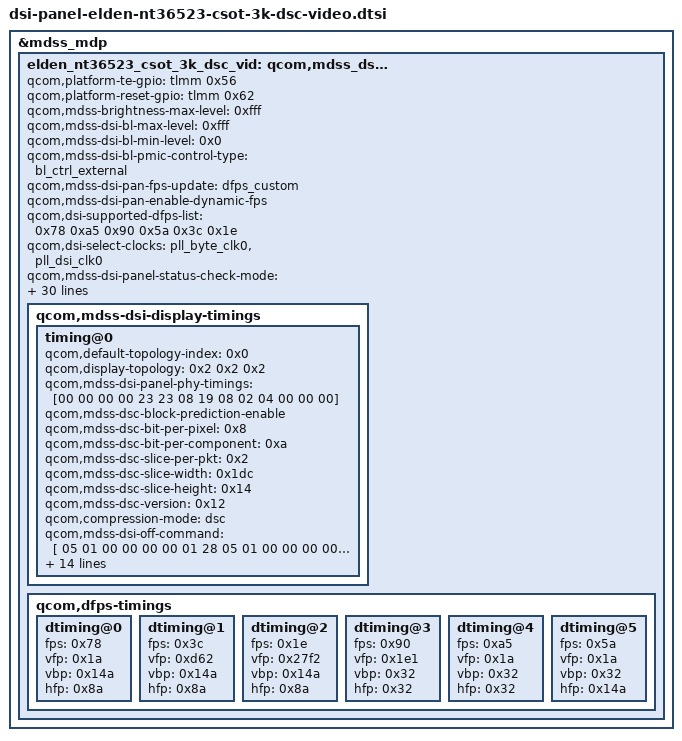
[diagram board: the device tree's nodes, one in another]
// SPDX-License-Identifier: GPL-2.0-only

&mdss_mdp {
	elden_nt36523_csot_3k_dsc_vid: qcom,mdss_dsi_elden_nt36523_csot_3k_dsc_vid {
		qcom,platform-te-gpio = <&tlmm 0x56 0x0>;
		qcom,platform-reset-gpio = <&tlmm 0x62 0x0>;
		qcom,mdss-brightness-max-level = <0xfff>;
		qcom,mdss-dsi-bl-max-level = <0xfff>;
		qcom,mdss-dsi-bl-min-level = <0x0>;
		qcom,mdss-dsi-bl-pmic-control-type = "bl_ctrl_external";
		qcom,mdss-dsi-pan-fps-update = "dfps_custom";
		qcom,mdss-dsi-pan-enable-dynamic-fps;
		qcom,dsi-supported-dfps-list = <0x78 0xa5 0x90 0x5a 0x3c 0x1e>;
		qcom,dsi-select-clocks = "pll_byte_clk0", "pll_dsi_clk0";
		qcom,mdss-dsi-panel-status-check-mode = "te_signal_check";
		qcom,esd-check-enabled;
		qcom,ulps-enabled;
		qcom,mdss-dsi-panel-blackness-level = <0xc9e>;
		qcom,mdss-dsi-panel-peak-brightness = <0x989680>;
		qcom,mdss-dsi-panel-hdr-color-primaries = <0x38a4 0x3c8c 0x7d00 0x4268 0x3c8c 0x7530 0x1f40 0xbb8>;
		qcom,mdss-dsi-panel-hdr-enabled;
		qcom,mdss-dsi-reset-sequence = <0x0 0xb 0x1 0x1 0x0 0x3 0x1 0xa>;
		qcom,mdss-dsi-lp11-init;
		qcom,mdss-pan-physical-height-dimension = <0xbe>;
		qcom,mdss-pan-physical-width-dimension = <0x76>;
		qcom,panel-cphy-mode;
		qcom,mdss-dsi-mdp-trigger = "none";
		qcom,mdss-dsi-dma-trigger = "trigger_sw";
		qcom,mdss-dsi-lane-2-state;
		qcom,mdss-dsi-lane-1-state;
		qcom,mdss-dsi-lane-0-state;
		qcom,mdss-dsi-bllp-eof-power-mode;
		qcom,mdss-dsi-bllp-power-mode;
		qcom,mdss-dsi-traffic-mode = "burst_mode";
		qcom,mdss-dsi-bpp = <0x1e>;
		qcom,mdss-dsi-stream = <0x0>;
		qcom,mdss-dsi-virtual-channel-id = <0x0>;
		qcom,dsi-phy-num = <0x0 0x1>;
		qcom,dsi-ctrl-num = <0x0 0x1>;
		qcom,mdss-dsi-panel-type = "dsi_video_mode";
		qcom,mdss-dsi-panel-name = "nt36523 3k fhd plus 165Hz CPHY video panel";

		qcom,mdss-dsi-display-timings {

			timing@0 {
				qcom,default-topology-index = <0x0>;
				qcom,display-topology = <0x2 0x2 0x2>;
				qcom,mdss-dsi-panel-phy-timings = [00 00 00 00 23 23 08 19 08 02 04 00 00 00];
				qcom,mdss-dsc-block-prediction-enable;
				qcom,mdss-dsc-bit-per-pixel = <0x8>;
				qcom,mdss-dsc-bit-per-component = <0xa>;
				qcom,mdss-dsc-slice-per-pkt = <0x2>;
				qcom,mdss-dsc-slice-width = <0x1dc>;
				qcom,mdss-dsc-slice-height = <0x14>;
				qcom,mdss-dsc-version = <0x12>;
				qcom,compression-mode = "dsc";
				qcom,mdss-dsi-off-command = [
					05 01 00 00 00 00 01 28
					05 01 00 00 00 00 01 10
				];
				qcom,mdss-dsi-on-command-state = "dsi_lp_mode";
				qcom,mdss-dsi-on-command = [
					39 01 00 00 00 00 02 ff 20
					39 01 00 00 00 00 02 fb 01
					39 01 00 00 00 00 02 30 50
					39 01 00 00 00 00 02 ff 23
					39 01 00 00 00 00 02 fb 01
					39 01 00 00 00 00 02 89 a4
					39 01 00 00 00 00 02 ff 26
					39 01 00 00 00 00 02 fb 01
					39 01 00 00 00 00 04 cd 8f a9 00
					39 01 00 00 00 00 04 ce 8c a9 00
					39 01 00 00 00 00 02 ff 27
					39 01 00 00 00 00 02 fb 01
					39 01 00 00 00 00 02 79 22
					39 01 00 00 00 00 02 d0 31
					39 01 00 00 00 00 03 d1 08 08
					39 01 00 00 00 00 02 d2 08
					39 01 00 00 00 00 02 ff d0
					39 01 00 00 00 00 02 fb 01
					39 01 00 00 00 00 02 00 31
					39 01 00 00 00 00 02 09 ee
					39 01 00 00 00 00 02 1c 77
					39 01 00 00 00 00 02 1d 07
					39 01 00 00 00 00 02 ff e0
					39 01 00 00 00 00 02 fb 01
					39 01 00 00 00 00 02 bb 00
					39 01 00 00 00 00 02 ff f0
					39 01 00 00 00 00 02 fb 01
					39 01 00 00 00 00 02 e6 02
					39 01 00 00 00 00 02 ff 10
					39 01 00 00 00 00 02 fb 01
					39 01 00 00 00 00 0a 3b 03 4e 1a 04 04 01 80 36 36
					39 01 00 00 00 00 02 60 00
					39 01 00 00 00 00 03 90 03 00
					39 01 00 00 00 00 11 91 ab a8 00 14 d2 00 00 00 01 b9 00 06 05 7a 05 b8
					39 01 00 00 00 00 03 92 10 e0
					39 01 00 00 00 00 03 b2 91 80
					39 01 00 00 00 00 02 b3 40
					05 01 00 00 69 00 01 11
					05 01 00 00 28 00 01 29
				];
				qcom,mdss-dsi-panel-framerate = <0x78>;
				qcom,mdss-dsi-panel-clockrate = <0x2d381490>;
				qcom,mdss-dsi-v-pulse-width = <0x4>;
				qcom,mdss-dsi-v-front-porch = <0x1a>;
				qcom,mdss-dsi-v-back-porch = <0x14a>;
				qcom,mdss-dsi-h-sync-skew = <0x0>;
				qcom,mdss-dsi-h-pulse-width = <0x10>;
				qcom,mdss-dsi-h-back-porch = <0x10>;
				qcom,mdss-dsi-h-front-porch = <0x8a>;
				qcom,mdss-dsi-panel-height = <0xbe0>;
				qcom,mdss-dsi-panel-width = <0x3b8>;
			};
		};

		qcom,dfps-timings {

			dtiming@0 {
				fps = <0x78>;
				vfp = <0x1a>;
				vbp = <0x14a>;
				hfp = <0x8a>;
			};

			dtiming@1 {
				fps = <0x3c>;
				vfp = <0xd62>;
				vbp = <0x14a>;
				hfp = <0x8a>;
			};

			dtiming@2 {
				fps = <0x1e>;
				vfp = <0x27f2>;
				vbp = <0x14a>;
				hfp = <0x8a>;
			};

			dtiming@3 {
				fps = <0x90>;
				vfp = <0x1e1>;
				vbp = <0x32>;
				hfp = <0x32>;
			};

			dtiming@4 {
				fps = <0xa5>;
				vfp = <0x1a>;
				vbp = <0x32>;
				hfp = <0x32>;
			};

			dtiming@5 {
				fps = <0x5a>;
				vfp = <0x1a>;
				vbp = <0x32>;
				hfp = <0x14a>;
			};
		};
	};
};
